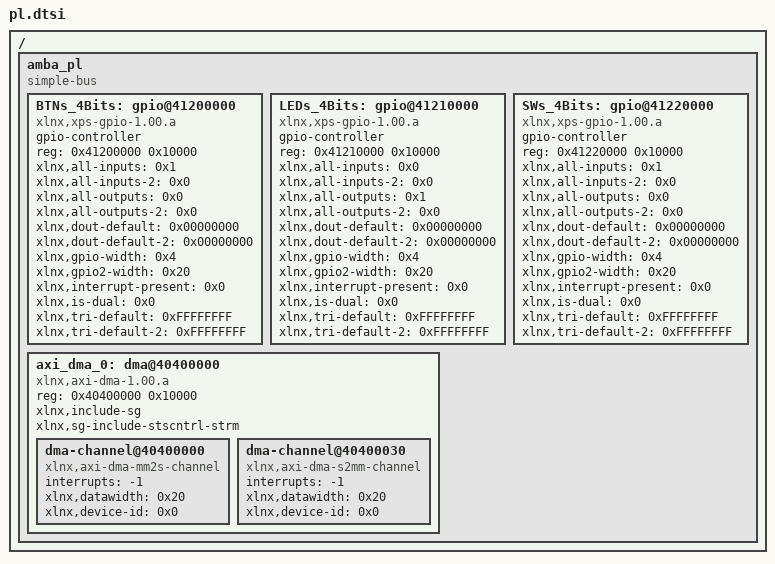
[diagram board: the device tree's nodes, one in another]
/*
 * CAUTION: This file is automatically generated by Xilinx.
 * Version:  
 * Today is: Thu Jun 29 17:39:10 2017
*/


/ {
	amba_pl: amba_pl {
		#address-cells = <1>;
		#size-cells = <1>;
		compatible = "simple-bus";
		ranges ;
		BTNs_4Bits: gpio@41200000 {
			#gpio-cells = <2>;
			compatible = "xlnx,xps-gpio-1.00.a";
			gpio-controller ;
			reg = <0x41200000 0x10000>;
			xlnx,all-inputs = <0x1>;
			xlnx,all-inputs-2 = <0x0>;
			xlnx,all-outputs = <0x0>;
			xlnx,all-outputs-2 = <0x0>;
			xlnx,dout-default = <0x00000000>;
			xlnx,dout-default-2 = <0x00000000>;
			xlnx,gpio-width = <0x4>;
			xlnx,gpio2-width = <0x20>;
			xlnx,interrupt-present = <0x0>;
			xlnx,is-dual = <0x0>;
			xlnx,tri-default = <0xFFFFFFFF>;
			xlnx,tri-default-2 = <0xFFFFFFFF>;
		};
		LEDs_4Bits: gpio@41210000 {
			#gpio-cells = <2>;
			compatible = "xlnx,xps-gpio-1.00.a";
			gpio-controller ;
			reg = <0x41210000 0x10000>;
			xlnx,all-inputs = <0x0>;
			xlnx,all-inputs-2 = <0x0>;
			xlnx,all-outputs = <0x1>;
			xlnx,all-outputs-2 = <0x0>;
			xlnx,dout-default = <0x00000000>;
			xlnx,dout-default-2 = <0x00000000>;
			xlnx,gpio-width = <0x4>;
			xlnx,gpio2-width = <0x20>;
			xlnx,interrupt-present = <0x0>;
			xlnx,is-dual = <0x0>;
			xlnx,tri-default = <0xFFFFFFFF>;
			xlnx,tri-default-2 = <0xFFFFFFFF>;
		};
		SWs_4Bits: gpio@41220000 {
			#gpio-cells = <2>;
			compatible = "xlnx,xps-gpio-1.00.a";
			gpio-controller ;
			reg = <0x41220000 0x10000>;
			xlnx,all-inputs = <0x1>;
			xlnx,all-inputs-2 = <0x0>;
			xlnx,all-outputs = <0x0>;
			xlnx,all-outputs-2 = <0x0>;
			xlnx,dout-default = <0x00000000>;
			xlnx,dout-default-2 = <0x00000000>;
			xlnx,gpio-width = <0x4>;
			xlnx,gpio2-width = <0x20>;
			xlnx,interrupt-present = <0x0>;
			xlnx,is-dual = <0x0>;
			xlnx,tri-default = <0xFFFFFFFF>;
			xlnx,tri-default-2 = <0xFFFFFFFF>;
		};
		axi_dma_0: dma@40400000 {
			#dma-cells = <1>;
			compatible = "xlnx,axi-dma-1.00.a";
			reg = <0x40400000 0x10000>;
			xlnx,include-sg ;
			xlnx,sg-include-stscntrl-strm ;
			dma-channel@40400000 {
				compatible = "xlnx,axi-dma-mm2s-channel";
				interrupts = <-1>;
				xlnx,datawidth = <0x20>;
				xlnx,device-id = <0x0>;
			};
			dma-channel@40400030 {
				compatible = "xlnx,axi-dma-s2mm-channel";
				interrupts = <-1>;
				xlnx,datawidth = <0x20>;
				xlnx,device-id = <0x0>;
			};
		};
	};
};
